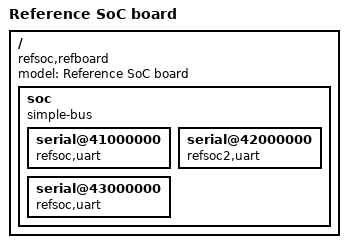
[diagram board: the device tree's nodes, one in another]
/dts-v1/;

/ {
	#address-cells = <0x1>;
	#size-cells = <0x1>;
	model = "Reference SoC board";
	compatible = "refsoc,refboard";

	soc {
		#address-cells = <0x1>;
		#size-cells = <0x1>;
		compatible = "simple-bus";
		ranges;

		/* Node with one compat - has matching binding */
		serial@41000000 {
			compatible = "refsoc,uart";
		};

		/* Node with one compat - has other matching binding */
		serial@42000000 {
			compatible = "refsoc2,uart";
		};

		/* Node with two compats, both compats have binding */
		serial@43000000 {
			compatible = "refsoc,uart", "refsoc2,uart";
		};
	};
};
